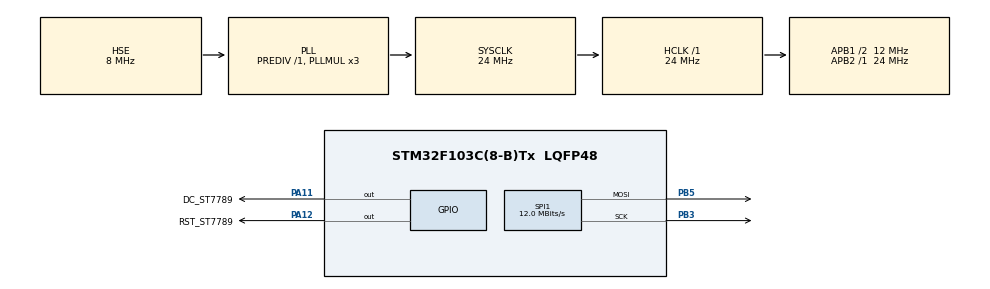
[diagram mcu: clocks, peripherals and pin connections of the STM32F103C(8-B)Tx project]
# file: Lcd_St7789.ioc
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Dma.Request0=SPI1_TX
Dma.SPI1_TX.0.Direction=DMA_MEMORY_TO_PERIPH
Dma.SPI1_TX.0.Instance=DMA1_Channel3
Dma.SPI1_TX.0.MemDataAlignment=DMA_MDATAALIGN_BYTE
Dma.SPI1_TX.0.MemInc=DMA_MINC_ENABLE
Dma.SPI1_TX.0.Mode=DMA_NORMAL
Dma.SPI1_TX.0.PeriphDataAlignment=DMA_PDATAALIGN_BYTE
Dma.SPI1_TX.0.PeriphInc=DMA_PINC_DISABLE
Dma.SPI1_TX.0.Priority=DMA_PRIORITY_LOW
Mcu.Family=STM32F1
Mcu.Name=STM32F103C(8-B)Tx
Mcu.Package=LQFP48
NVIC.DMA1_Channel3_IRQn=true\:0\:0\:false\:false\:true\:false\:true
NVIC.PriorityGroup=NVIC_PRIORITYGROUP_4
PA11.GPIO_Label=DC_ST7789
PA11.GPIO_Speed=GPIO_SPEED_FREQ_HIGH
PA11.PinState=GPIO_PIN_SET
PA11.Signal=GPIO_Output
PA12.GPIO_Label=RST_ST7789
PA12.GPIO_Speed=GPIO_SPEED_FREQ_HIGH
PA12.PinState=GPIO_PIN_RESET
PA12.Signal=GPIO_Output
PA13.Mode=Serial_Wire
PA13.Signal=SYS_JTMS-SWDIO
PA14.Mode=Serial_Wire
PA14.Signal=SYS_JTCK-SWCLK
PB3.Mode=TX_Only_Simplex_Unidirect_Master
PB3.Signal=SPI1_SCK
PB5.Mode=TX_Only_Simplex_Unidirect_Master
PB5.Signal=SPI1_MOSI
PD0-OSC_IN.Mode=HSE-External-Oscillator
PD0-OSC_IN.Signal=RCC_OSC_IN
PD1-OSC_OUT.Mode=HSE-External-Oscillator
PD1-OSC_OUT.Signal=RCC_OSC_OUT
ProjectManager.HeapSize=0x200
ProjectManager.StackSize=0x400
ProjectManager.TargetToolchain=MDK-ARM V5.32
RCC.AHBFreq_Value=24000000
RCC.APB1CLKDivider=RCC_HCLK_DIV2
RCC.APB1Freq_Value=12000000
RCC.APB1TimFreq_Value=24000000
RCC.APB2Freq_Value=24000000
RCC.APB2TimFreq_Value=24000000
RCC.HCLKFreq_Value=24000000
RCC.PLLMUL=RCC_PLL_MUL3
RCC.PLLSourceVirtual=RCC_PLLSOURCE_HSE
RCC.SYSCLKFreq_VALUE=24000000
RCC.SYSCLKSource=RCC_SYSCLKSOURCE_PLLCLK
RCC.USBFreq_Value=24000000
SPI1.BaudRatePrescaler=SPI_BAUDRATEPRESCALER_2
SPI1.CLKPhase=SPI_PHASE_1EDGE
SPI1.CLKPolarity=SPI_POLARITY_HIGH
SPI1.CalculateBaudRate=12.0 MBits/s
SPI1.Direction=SPI_DIRECTION_2LINES
SPI1.Mode=SPI_MODE_MASTER
SPI1.VirtualType=VM_MASTER
board=custom

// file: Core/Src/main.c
/* USER CODE BEGIN Header */
/**
  ******************************************************************************
  * @file           : main.c
  * @brief          : Main program body
  ******************************************************************************
  * @attention
  *
  * Copyright (c) 2022 STMicroelectronics.
  * All rights reserved.
  *
  * This software is licensed under terms that can be found in the LICENSE file
  * in the root directory of this software component.
  * If no LICENSE file comes with this software, it is provided AS-IS.
  *
  ******************************************************************************
  */
/* USER CODE END Header */
#include "main.h"
#include "st7789.h"

SPI_HandleTypeDef hspi1;
DMA_HandleTypeDef hdma_spi1_tx;

void SystemClock_Config(void);
static void MX_GPIO_Init(void);
static void MX_DMA_Init(void);
static void MX_SPI1_Init(void);

void    LL_mDelay(uint32_t Delay);

int main(void)
{

  /* MCU Configuration--------------------------------------------------------*/

  /* Reset of all peripherals, Initializes the Flash interface and the Systick. */
  HAL_Init();

  /* Configure the system clock */
  SystemClock_Config();

  /* Initialize all configured peripherals */
  MX_GPIO_Init();
  MX_DMA_Init();
  MX_SPI1_Init();
	ST7789_Init();
	ST7789_FillScreen(BLACK);
//	conversion_ready = 1;
//	trigger_point = 1;

  /* USER CODE BEGIN 2 */
//	ST7789_WriteString(24, 102, "OSCILLOSCOPE", Font_16x26, WHITE, BLACK);
//	ST7789_WriteString(50, 130, "Sampling Rate 1MSa/s", Font_7x10, WHITE, BLACK);
//	LL_mDelay(1000);
//	ST7789_WriteString(46, 130, "       Vanan92       ", Font_7x10, WHITE, BLACK);
//	LL_mDelay(1000);
//	ST7789_WriteString(50, 130, "        V1.1        ", Font_7x10, WHITE, BLACK);
//	LL_mDelay(1000);

//		ST7789_FillScreen(BLUE);
//	LL_mDelay(1000);
//		ST7789_FillScreen(WHITE);
//	LL_mDelay(1000);
//		ST7789_FillScreen(RED);
//	LL_mDelay(1000);
//	ST7789_WriteString(20, 20, "WELLCOME @@", Font_16x26, WHITE, RED);
//	LL_mDelay(2000);
//
//	lcd_clear(WHITE);

  /* USER CODE END 2 */

  /* Infinite loop */
  /* USER CODE BEGIN WHILE */
  while (1)
  {
//		ST7789_Init();
//		ST7789_FillScreen(BLACK);

//			ST7789_FillScreen(BLUE);
//		LL_mDelay(500);
//			ST7789_FillScreen(WHITE);
//		LL_mDelay(500);
//			ST7789_FillScreen(CYAN);
//		LL_mDelay(500);
//			ST7789_FillScreen(RED);
//		LL_mDelay(500);
//			ST7789_FillScreen(GREEN);
//		LL_mDelay(500);
//			ST7789_FillScreen(YELLOW);
//		LL_mDelay(500);
//				ST7789_FillScreen(BROWN);
//		LL_mDelay(500);
//			ST7789_FillScreen(DARKBLUE);
//		LL_mDelay(500);
//			ST7789_FillScreen(MAGENTA);
//		LL_mDelay(500);
//			ST7789_FillScreen(LIGHTGREEN);
//		LL_mDelay(500);
//			ST7789_FillScreen(LIGHTBLUE);
//		LL_mDelay(500);
//			ST7789_FillScreen(LGRAY);
//		LL_mDelay(500);
//			ST7789_FillScreen(LBBLUE);
//		LL_mDelay(500);
//			ST7789_FillScreen(LGRAYBLUE);
//		LL_mDelay(500);
//			ST7789_FillScreen(WHITE);
//		LL_mDelay(500);
//
//	ST7789_WriteString(10, 10, "Font test.", Font_16x26, GBLUE, WHITE);
//	ST7789_WriteString(10, 50, "Hello Steve!", Font_7x10, RED, WHITE);
//	ST7789_WriteString(10, 75, "Hello Steve!", Font_11x18, YELLOW, WHITE);
//	ST7789_WriteString(10, 100, "Hello Steve!", Font_16x26, MAGENTA, WHITE);
//	HAL_Delay(1000);

	ST7789_FillScreen(RED);
	ST7789_WriteString(10, 10, "Rect./Line.", Font_11x18, YELLOW, RED);
	ST7789_FillRectangle(30, 30, 100, 100, WHITE);
	HAL_Delay(1000);

	ST7789_FillScreen(RED);
	ST7789_WriteString(10, 10, "Circle.", Font_11x18, YELLOW, RED);
	ST7789_DrawCircle(60, 60, 25, WHITE);
	HAL_Delay(1000);

	ST7789_FillScreen(WHITE);
	ST7789_DrawImage(0, 0, 128, 128, (uint16_t *)saber);
	HAL_Delay(3000);

//	ST7789_FillScreen(WHITE);
//	ST7789_DrawImage(0, 0, 240, 240, (uint16_t *) tek);
//	HAL_Delay(3000);
	//lcd_clear(WHITE);
  }
  /* USER CODE END 3 */
}

void SystemClock_Config(void)
{
  RCC_OscInitTypeDef RCC_OscInitStruct = {0};
  RCC_ClkInitTypeDef RCC_ClkInitStruct = {0};

  /** Initializes the RCC Oscillators according to the specified parameters
  * in the RCC_OscInitTypeDef structure.
  */
  RCC_OscInitStruct.OscillatorType = RCC_OSCILLATORTYPE_HSE;
  RCC_OscInitStruct.HSEState = RCC_HSE_ON;
  RCC_OscInitStruct.HSEPredivValue = RCC_HSE_PREDIV_DIV1;
  RCC_OscInitStruct.HSIState = RCC_HSI_ON;
  RCC_OscInitStruct.PLL.PLLState = RCC_PLL_ON;
  RCC_OscInitStruct.PLL.PLLSource = RCC_PLLSOURCE_HSE;
  RCC_OscInitStruct.PLL.PLLMUL = RCC_PLL_MUL3;
  if (HAL_RCC_OscConfig(&RCC_OscInitStruct) != HAL_OK)
  {
    Error_Handler();
  }
  /** Initializes the CPU, AHB and APB buses clocks
  */
  RCC_ClkInitStruct.ClockType = RCC_CLOCKTYPE_HCLK|RCC_CLOCKTYPE_SYSCLK
                              |RCC_CLOCKTYPE_PCLK1|RCC_CLOCKTYPE_PCLK2;
  RCC_ClkInitStruct.SYSCLKSource = RCC_SYSCLKSOURCE_PLLCLK;
  RCC_ClkInitStruct.AHBCLKDivider = RCC_SYSCLK_DIV1;
  RCC_ClkInitStruct.APB1CLKDivider = RCC_HCLK_DIV2;
  RCC_ClkInitStruct.APB2CLKDivider = RCC_HCLK_DIV1;

  if (HAL_RCC_ClockConfig(&RCC_ClkInitStruct, FLASH_LATENCY_0) != HAL_OK)
  {
    Error_Handler();
  }
}

static void MX_SPI1_Init(void)
{

  /* SPI1 parameter configuration*/
  hspi1.Instance = SPI1;
  hspi1.Init.Mode = SPI_MODE_MASTER;
  hspi1.Init.Direction = SPI_DIRECTION_2LINES;
  hspi1.Init.DataSize = SPI_DATASIZE_8BIT;
  hspi1.Init.CLKPolarity = SPI_POLARITY_HIGH;
  hspi1.Init.CLKPhase = SPI_PHASE_1EDGE;
  hspi1.Init.NSS = SPI_NSS_SOFT;
  hspi1.Init.BaudRatePrescaler = SPI_BAUDRATEPRESCALER_2;
  hspi1.Init.FirstBit = SPI_FIRSTBIT_MSB;
  hspi1.Init.TIMode = SPI_TIMODE_DISABLE;
  hspi1.Init.CRCCalculation = SPI_CRCCALCULATION_DISABLE;
  hspi1.Init.CRCPolynomial = 10;
  if (HAL_SPI_Init(&hspi1) != HAL_OK)
  {
    Error_Handler();
  }

}

static void MX_DMA_Init(void)
{

  /* DMA controller clock enable */
  __HAL_RCC_DMA1_CLK_ENABLE();

  /* DMA interrupt init */
  /* DMA1_Channel3_IRQn interrupt configuration */
  HAL_NVIC_SetPriority(DMA1_Channel3_IRQn, 0, 0);
  HAL_NVIC_EnableIRQ(DMA1_Channel3_IRQn);

}

static void MX_GPIO_Init(void)
{
  GPIO_InitTypeDef GPIO_InitStruct = {0};

  /* GPIO Ports Clock Enable */
  __HAL_RCC_GPIOD_CLK_ENABLE();
  __HAL_RCC_GPIOA_CLK_ENABLE();
  __HAL_RCC_GPIOB_CLK_ENABLE();

  /*Configure GPIO pin Output Level */
  HAL_GPIO_WritePin(DC_ST7789_GPIO_Port, DC_ST7789_Pin, GPIO_PIN_SET);

  /*Configure GPIO pin Output Level */
  HAL_GPIO_WritePin(RST_ST7789_GPIO_Port, RST_ST7789_Pin, GPIO_PIN_RESET);

  /*Configure GPIO pins : DC_ST7789_Pin RST_ST7789_Pin */
  GPIO_InitStruct.Pin = DC_ST7789_Pin|RST_ST7789_Pin;
  GPIO_InitStruct.Mode = GPIO_MODE_OUTPUT_PP;
  GPIO_InitStruct.Pull = GPIO_NOPULL;
  GPIO_InitStruct.Speed = GPIO_SPEED_FREQ_HIGH;
  HAL_GPIO_Init(GPIOA, &GPIO_InitStruct);

}

void Error_Handler(void)
{
  __disable_irq();
  while (1)
  {
  }
}

void LL_mDelay(uint32_t Delay)
{
  __IO uint32_t  tmp = SysTick->CTRL;  /* Clear the COUNTFLAG first */
  /* Add this code to indicate that local variable is not used */
  ((void)tmp);

  /* Add a period to guaranty minimum wait */
  if (Delay < LL_MAX_DELAY)
  {
    Delay++;
  }

  while (Delay)
  {
    if ((SysTick->CTRL & SysTick_CTRL_COUNTFLAG_Msk) != 0U)
    {
      Delay--;
    }
  }
}
